# CM_CORE_AON__CKGEN register map
Vendor: Texas Instruments
Peripheral module from a debugger description file (folder DRA74xP_75xP_76xP_77xP).
Registers are 32-bit, access per field, reset values left out (the file's numbers can be read two ways) unless marked. A register's access mark holds for its fields unless they carry their own. Offsets are as the file gives them; lines under a group give offsets from that group; [hi:lo] are bit positions; {n}, {i} and the like mark numbered series; 'fields as' and 'values as' point back to an identical list; <NAME> marks a mode.

## CM_CORE_AON__CKGEN
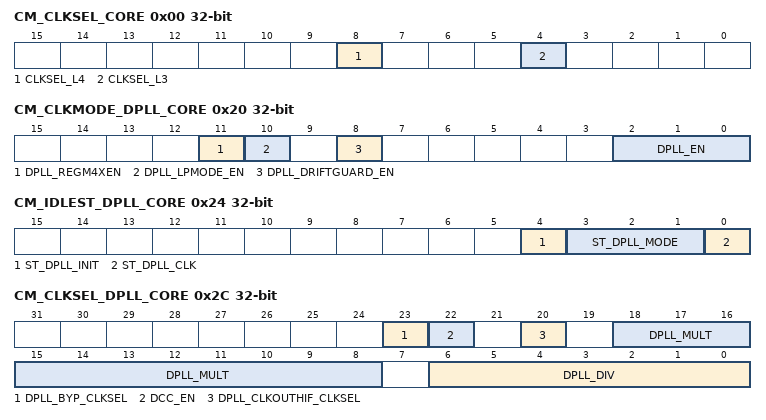
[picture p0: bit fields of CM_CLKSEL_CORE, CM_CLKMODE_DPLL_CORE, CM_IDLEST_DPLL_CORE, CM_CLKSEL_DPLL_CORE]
0x00 CM_CLKSEL_CORE — CORE module clock selection.
  [8] CLKSEL_L4 ro — Selects L4 interconnect clock (L4_clk)
    0=L3_CLK_DIV_1 (RESERVED); 1=L3_CLK_DIV_2 (L4_CLK is L3_CLK divided by 2)
  [4] CLKSEL_L3 rw — Selects L3 interconnect clock (L3_clk)
    0=CORE_CLK_DIV_1 (L3_CLK is CORE_CLK divided by 1); 1=CORE_CLK_DIV_2 (L3_CLK is CORE_CLK divided by 2)
0x08 CM_CLKSEL_ABE — ABE module clock selection.
  [1:0] CLKSEL_OPP rw — Selects the OPP divider ABE domain
    0=DIV_1 (ABE_CLK is divide by 1 of DPLL_ABE_X2_CLK); 1=DIV_2 (ABE_CLK is divide by 2 of DPLL_ABE_X2_CLK); 2=DIV_4 (ABE_CLK is divide by 4 of DPLL_ABE_X2_CLK)
0x10 CM_DLL_CTRL — Special register for DLL control
  [0] DLL_OVERRIDE rw — Control if DLL lock and code outputs are overriden or not
    0=NO_OVR; 1=OVR
0x20 CM_CLKMODE_DPLL_CORE — This register allows controlling the DPLL modes.
  [11] DPLL_REGM4XEN ro — Enable the REGM4XEN mode of the DPLL. Please check the DPLL documentation to check when this mode can be enabled.
    0=DISABLED (REGM4XEN mode of the DPLL is disabled)
  [10] DPLL_LPMODE_EN rw — Set the DPLL in Low Power mode. Check the DPLL documentation to see when this can be enabled.
    0=DISABLED (Low power mode of the DPLL is disabled); 1=ENABLED (Low power mode of the DPLL is enabled)
  [8] DPLL_DRIFTGUARD_EN rw — This bit allows to enable or disable the automatic recalibration feature of the DPLL. The DPLL will automatically start a recalibration process upon assertion of the DPLL's RECAL flag if this bit is set.
    0=DIASBLED (DRIFTGUARD feature is disabled); 1=ENABLED (DRIFTGUARD feature is enabled)
  [2:0] DPLL_EN rw — DPLL control.
    5=DPLL_LP_BYP_MODE (Put the DPLL in Idle Bypass Low Power mode.); 6=DPLL_FR_BYP_MODE (Put the DPLL in Idle Bypass Fast Relock mode.); 7=DPLL_LOCK_MODE (Enables the DPLL in Lock mode)
0x24 CM_IDLEST_DPLL_CORE ro — This register allows monitoring DPLL activity. This register is read only and automatically updated. [warm reset insensitive]
  [4] ST_DPLL_INIT — DPLL init status (for debug purpose).
    0=DPLL_NOTINIT; 1=DPLL_INIT
  [3:1] ST_DPLL_MODE — DPLL mode status (for debug purpose).
  [0] ST_DPLL_CLK — DPLL lock status
    0=DPLL_UNLOCKED; 1=DPLL_LOCKED
0x28 CM_AUTOIDLE_DPLL_CORE — This register provides automatic control over the DPLL activity.
  [2:0] AUTO_DPLL_MODE rw — DPLL automatic control.
    0=AUTO_CTL_DISABLE (DPLL auto control disabled); 1=AUTO_LP_STOP (The DPLL is automatically put in Low Power Stop mode when its DPLL generated clocks are not required anymore. It is also restarted automatically.); 2=AUTO_FR_STOP (The DPLL is automatically put in Fast Relock Stop mode when its DPLL generated clocks are not required anymore. It is also restarted automatically.); 5=AUTO_LP_BYP (The DPLL is automatically put in Idle Bypass Low Power mode when its DPLL generated clocks are not required anymore. It is also restarted automatically.); 6=AUTO_FR_BYP (The DPLL is automatically put in Idle Bypass Fast Relock mode when its DPLL generated clocks are not required anymore. It is also restarted automatically.)
0x2C CM_CLKSEL_DPLL_CORE — This register provides controls over the DPLL.
  [23] DPLL_BYP_CLKSEL rw — Allows control of the BYPASS clock of the PLL and the associated HSDIVIDER. Same as ULOWCLKEN on DPLL. In DPLL Locked mode, 0 - No impact 1 - No impact In DPLL Bypass mode, 0 - CLKINP is selected as the BYPASS clock for CLKOUT/CLKOUTX2 1 - CLKINPULOW is selected as the BYPASS clock for CLKOUT/CLKOUTX2
  [22] DCC_EN ro — Duty-cycle corrector for high frequency clock
    0=DISABLED (Duty-cycle corrector is disabled)
  [20] DPLL_CLKOUTHIF_CLKSEL rw — Selects the source of the DPLL CLKOUTHIF clock. Same as CLKINPHIFSEL pin on the DPLL
    0=SEL_DCO (CLKOUTHIF is generated from the DPLL oscillator (DCO)); 1=SEL_CLKINPHIF (CLKOUTHIF is generated from CLKINPHIF)
  [18:8] DPLL_MULT rw — DPLL multiplier factor (2 to 2047). (equal to input M of DPLL; M=2 to 2047 = DPLL multiplies by M). [warm reset insensitive]
  [6:0] DPLL_DIV rw — DPLL divider factor (0 to 127) (equal to input N of DPLL; actual division factor is N+1). [warm reset insensitive]
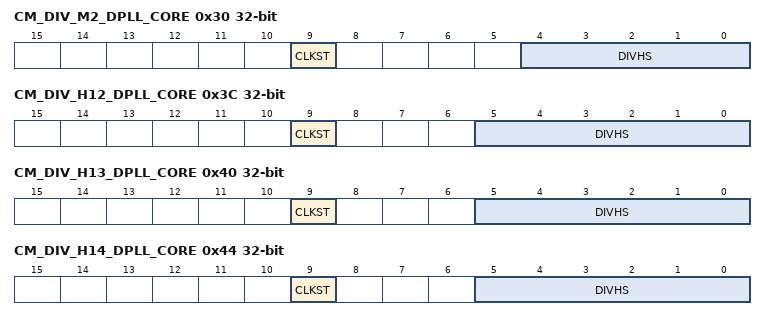
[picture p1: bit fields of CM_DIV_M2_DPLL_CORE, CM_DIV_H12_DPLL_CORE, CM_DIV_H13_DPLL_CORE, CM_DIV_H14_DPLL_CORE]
0x30 CM_DIV_M2_DPLL_CORE — This register provides controls over the M2 divider of the DPLL.
  [9] CLKST ro — DPLL CLKOUT status
    0=CLK_GATED (The clock output is gated); 1=CLK_ENABLED (The clock output is enabled)
  [4:0] DIVHS rw — This field programs the M2 post-divider factor (1 to 31) of DPLL_CORE.... .
    1=M2_=_/1; 2=M2_=_/2; 31=RESERVED (M2 = /31)
0x3C CM_DIV_H12_DPLL_CORE — This register provides controls over the CLKOUT2 o/p of the HSDIVIDER1.
  [9] CLKST ro — HSDIVIDER1 CLKOUT2 status
    values as CM_DIV_M2_DPLL_CORE.CLKST
  [5:0] DIVHS rw — This field programs the H12 post-divider factor (1 to 63) of DPLL_CORE.... .
    1=H12_=_/1; 2=H12_=_/2; 63=RESERVED (H12 = /63)
0x40 CM_DIV_H13_DPLL_CORE — This register provides controls over the CLKOUT3 o/p of the HSDIVIDER1.
  [9] CLKST ro — HSDIVIDER1 CLKOUT3 status
    values as CM_DIV_M2_DPLL_CORE.CLKST
  [5:0] DIVHS rw — This field programs the H13 post-divider factor (1 to 63) of DPLL_CORE.... .
    1=H13_=_/1; 2=H13_=_/2; 63=RESERVED (H13 = /63)
0x44 CM_DIV_H14_DPLL_CORE — This register provides controls over the CLKOUT4 o/p of the HSDIVIDER1.
  [9] CLKST ro — HSDIVIDER1 CLKOUT4 status
    values as CM_DIV_M2_DPLL_CORE.CLKST
  [5:0] DIVHS rw — This field programs the H14 post-divider factor (1 to 63) of DPLL_CORE. When a value of 63 is programmed in this register, HS divider will perform division by 2.5 that is divided by 2 at top level.... .
    1=H14_=_/1; 2=H14_=_/2; 63=RESERVED (H14 = /63)
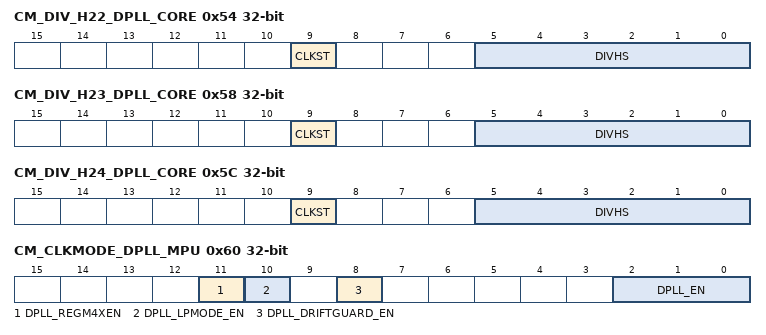
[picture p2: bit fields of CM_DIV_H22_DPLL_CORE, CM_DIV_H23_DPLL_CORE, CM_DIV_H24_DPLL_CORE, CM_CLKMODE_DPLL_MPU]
0x54 CM_DIV_H22_DPLL_CORE — This register provides controls over the CLKOUT2 o/p of the 2nd HSDIVIDER.
  [9] CLKST ro — HSDIVIDER2 CLKOUT2 status
    values as CM_DIV_M2_DPLL_CORE.CLKST
  [5:0] DIVHS rw — This field programs the H22 post-divider factor (1 to 63) of DPLL_CORE.... .
    1=H22_=_/1; 2=H22_=_/2; 63=RESERVED (H22 = /63)
0x58 CM_DIV_H23_DPLL_CORE — This register provides controls over the CLKOUT3 o/p of the 2nd HSDIVIDER.
  [9] CLKST ro — HSDIVIDER2 CLKOUT3 status
    values as CM_DIV_M2_DPLL_CORE.CLKST
  [5:0] DIVHS rw — This field programs the H23 post-divider factor (1 to 63) of DPLL_CORE.... .
    1=H23_=_/1; 2=H23_=_/2; 63=RESERVED (H23 = /63)
0x5C CM_DIV_H24_DPLL_CORE — This register provides controls over the CLKOUT4 o/p of the 2nd HSDIVIDER.
  [9] CLKST ro — HSDIVIDER2 CLKOUT4 status
    values as CM_DIV_M2_DPLL_CORE.CLKST
  [5:0] DIVHS rw — This field programs the H24 post-divider factor (1 to 63) of DPLL_CORE.... .
    1=H24_=_/1; 2=H24_=_/2; 63=RESERVED (H24 = /63)
0x60 CM_CLKMODE_DPLL_MPU — This register allows controlling the DPLL modes.
  fields as CM_CLKMODE_DPLL_CORE
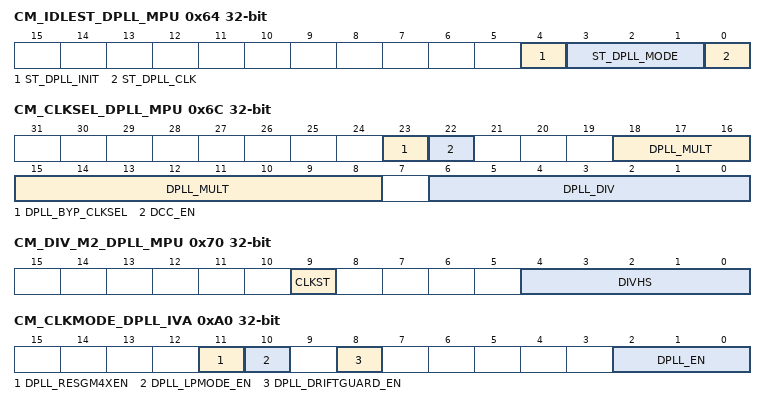
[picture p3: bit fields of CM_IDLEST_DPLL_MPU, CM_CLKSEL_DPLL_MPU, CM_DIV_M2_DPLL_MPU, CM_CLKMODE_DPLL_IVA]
0x64 CM_IDLEST_DPLL_MPU ro — This register allows monitoring DPLL activity. This register is read only and automatically updated. [warm reset insensitive]
  [4] ST_DPLL_INIT — DPLL init status (for debug purpose).
    0=DPLL_NOTINIT (DPLL is not init); 1=DPLL_INIT (DPLL has been init)
  [3:1] ST_DPLL_MODE — DPLL mode status (for debug purpose).
    0=TRANSIENT (Transient state. From reset to any LP idle state or from any power state to any power state (Power states are Low Power Stop mode, Fast Relock Stop mode, Idle Bypass Low Power mode and Idle Bypass Fast Relock mode).); 1=LP_STOP (The DPLL is in Low Power Stop mode.); 2=FR_STOP (The DPLL is in Fast Relock Stop mode.); 5=LP_BYP (The DPLL is in Idle Bypass Low Power mode.); 6=FR_BYP (The DPLL is in Idle Bypass Fast Relock mode.)
  [0] ST_DPLL_CLK — DPLL lock status
    0=DPLL_UNLOCKED (DPLL is either in bypass mode or in stop mode.); 1=DPLL_LOCKED (DPLL is LOCKED)
0x68 CM_AUTOIDLE_DPLL_MPU — This register provides automatic control over the DPLL activity.
  [2:0] AUTO_DPLL_MODE rw — DPLL automatic control;
    values as CM_AUTOIDLE_DPLL_CORE.AUTO_DPLL_MODE
0x6C CM_CLKSEL_DPLL_MPU — This register provides controls over the DPLL.
  [23] DPLL_BYP_CLKSEL ro — Only CLKINPULOW bypass clock supported for this PLL
  [22] DCC_EN rw — Duty-cycle corrector for high frequency clock
    0=DISABLED (Duty-cycle corrector is disabled); 1=ENABLED (Duty-cycle corrector is enabled)
  [18:8] DPLL_MULT rw — DPLL multiplier factor (2 to 2047). (equal to input M of DPLL; M=2 to 2047 = DPLL multiplies by M). [warm reset insensitive]
  [6:0] DPLL_DIV rw — DPLL divider factor (0 to 127) (equal to input N of DPLL; actual division factor is N+1). [warm reset insensitive]
0x70 CM_DIV_M2_DPLL_MPU — This register provides controls over the M2 divider of the DPLL.
  [9] CLKST ro — DPLL CLKOUT status
    values as CM_DIV_M2_DPLL_CORE.CLKST
  [4:0] DIVHS rw — This field programs the M2 post-divider factor (1 to 31) of DPLL_MPU.... .
    1=M2_=_/1; 2=M2_=_/2; 31=RESERVED (M2 = /31)
0x9C CM_BYPCLK_DPLL_MPU — Control MPU PLL BYPASS clock. [warm reset insensitive]
  [1:0] CLKSEL rw — Select the DPLL MPU bypass clock
0xA0 CM_CLKMODE_DPLL_IVA — This register allows controlling the DPLL modes.
  [11] DPLL_RESGM4XEN ro — Enable the REGM4XEN mode of the DPLL. Please check the DPLL documentation to check when this mode can be enabled.
    0=DISABLED (REGM4XEN mode of the DPLL is disabled)
  [10] DPLL_LPMODE_EN rw — Set the DPLL in Low Power mode. Check the DPLL documentation to see when this can be enabled.
    values as CM_CLKMODE_DPLL_CORE.DPLL_LPMODE_EN
  [8] DPLL_DRIFTGUARD_EN rw — This bit allows to enable or disable the automatic recalibration feature of the DPLL. The DPLL will automatically start a recalibration process upon assertion of the DPLL's RECAL flag if this bit is set.
    values as CM_CLKMODE_DPLL_CORE.DPLL_DRIFTGUARD_EN
  [2:0] DPLL_EN rw — DPLL control.
    values as CM_CLKMODE_DPLL_CORE.DPLL_EN
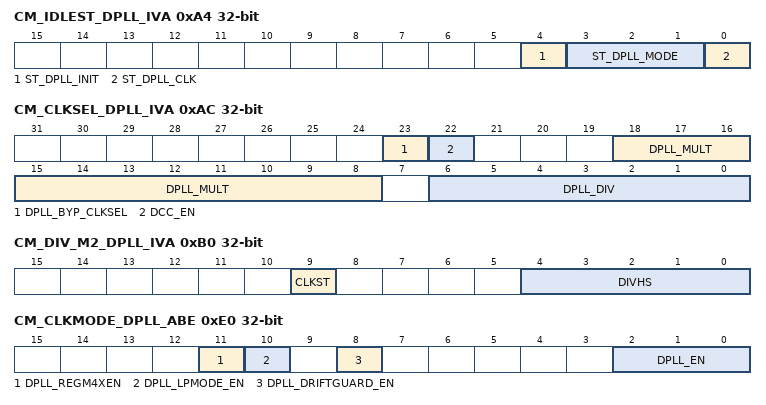
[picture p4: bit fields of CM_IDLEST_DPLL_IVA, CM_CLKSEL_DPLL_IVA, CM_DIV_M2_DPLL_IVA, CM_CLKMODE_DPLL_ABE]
0xA4 CM_IDLEST_DPLL_IVA ro — This register allows monitoring DPLL activity. This register is read only and automatically updated. [warm reset insensitive]
  [4] ST_DPLL_INIT — DPLL init status (for debug purpose)
    values as CM_IDLEST_DPLL_MPU.ST_DPLL_INIT
  [3:1] ST_DPLL_MODE — DPLL mode status (for debug purpose).
    values as CM_IDLEST_DPLL_MPU.ST_DPLL_MODE
  [0] ST_DPLL_CLK — DPLL lock status
    values as CM_IDLEST_DPLL_MPU.ST_DPLL_CLK
0xA8 CM_AUTOIDLE_DPLL_IVA — This register provides automatic control over the DPLL activity.
  fields as CM_AUTOIDLE_DPLL_MPU
0xAC CM_CLKSEL_DPLL_IVA — This register provides controls over the DPLL.
  [23] DPLL_BYP_CLKSEL rw — Allows control of the BYPASS clock of the PLL and the associated HSDIVIDER. Same as ULOWCLKEN on DPLL. In DPLL Locked mode, 0 - No impact 1 - No impact In DPLL Bypass mode, 0 - CLKINP is selected as the BYPASS clock for CLKOUT/CLKOUTX2 1 - CLKINPULOW is selected as the BYPASS clock for CLKOUT/CLKOUTX2
  [22] DCC_EN ro — Duty-cycle corrector for high frequency clock
    0=DISABLED (Duty-cycle corrector is disabled)
  [18:8] DPLL_MULT rw — DPLL multiplier factor (2 to 2047). (equal to input M of DPLL; M=2 to 2047 = DPLL multiplies by M). [warm reset insensitive]
  [6:0] DPLL_DIV rw — DPLL divider factor (0 to 127) (equal to input N of DPLL; actual division factor is N+1). [warm reset insensitive]
0xB0 CM_DIV_M2_DPLL_IVA — This register provides controls over the M2 divider of the DPLL.
  [9] CLKST ro — DPLL CLKOUT status
    values as CM_DIV_M2_DPLL_CORE.CLKST
  [4:0] DIVHS rw — This field programs the M2 post-divider factor (1 to 31) of DPLL_IVA.... .
    1=M2_=_/1; 2=M2_=_/2; 31=RESERVED (M2 = /31)
0xDC CM_BYPCLK_DPLL_IVA — Control IVA PLL BYPASS clock. [warm reset insensitive]
  [1:0] CLKSEL rw — Select the DPLL IVA bypass clock
    0=CORE_X2_CLK_DIV_1 (DPLL_IVA bypass clock is CORE_X2_CLK divided by 1); 1=CORE_X2_CLK_DIV_2 (DPLL_IVA bypass clock is CORE_X2_CLK divided by 2); 2=CORE_X2_CLK_DIV_4 (DPLL_IVA bypass clock is CORE_X2_CLK divided by 4); 3=CORE_X2_CLK_DIV_8 (DPLL_IVA bypass clock is CORE_X2_CLK divided by 8)
0xE0 CM_CLKMODE_DPLL_ABE — This register allows controlling the DPLL modes.
  [11] DPLL_REGM4XEN rw — Enable the REGM4XEN mode of the DPLL. Please check the DPLL documentation to check when this mode can be enabled.
    0=DISABLED (REGM4XEN mode of the DPLL is disabled); 1=ENABLE (REGM4XEN mode of the DPLL is enabled)
  [10] DPLL_LPMODE_EN rw — Set the DPLL in Low Power mode. Check the DPLL documentation to see when this can be enabled.
    values as CM_CLKMODE_DPLL_CORE.DPLL_LPMODE_EN
  [8] DPLL_DRIFTGUARD_EN rw — This bit allows to enable or disable the automatic recalibration feature of the DPLL. The DPLL will automatically start a recalibration process upon assertion of the DPLL's RECAL flag if this bit is set.
    values as CM_CLKMODE_DPLL_CORE.DPLL_DRIFTGUARD_EN
  [2:0] DPLL_EN rw — DPLL control.
    values as CM_CLKMODE_DPLL_CORE.DPLL_EN
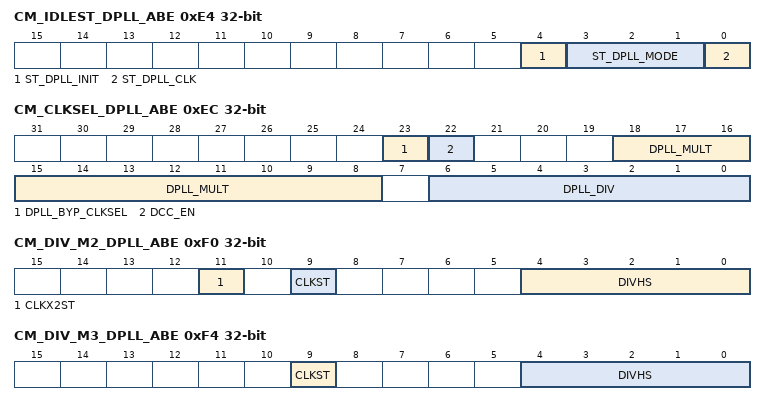
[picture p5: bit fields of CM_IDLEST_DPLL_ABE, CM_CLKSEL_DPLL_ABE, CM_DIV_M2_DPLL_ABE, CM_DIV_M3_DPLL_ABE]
0xE4 CM_IDLEST_DPLL_ABE ro — This register allows monitoring DPLL activity. This register is read only and automatically updated. [warm reset insensitive]
  fields as CM_IDLEST_DPLL_MPU
0xE8 CM_AUTOIDLE_DPLL_ABE — This register provides automatic control over the DPLL activity.
  [2:0] AUTO_DPLL_MODE rw — DPLL automatic control;
0xEC CM_CLKSEL_DPLL_ABE — This register provides controls over the DPLL.
  [23] DPLL_BYP_CLKSEL ro — Only CLKINPULOW bypass clock supported for this PLL
  [22] DCC_EN ro — Duty-cycle corrector for high frequency clock
    0=DISABLED (Duty-cycle corrector is disabled)
  [18:8] DPLL_MULT rw — DPLL multiplier factor (2 to 2047). (equal to input M of DPLL; M=2 to 2047 = DPLL multiplies by M). [warm reset insensitive]
  [6:0] DPLL_DIV rw — DPLL divider factor (0 to 127) (equal to input N of DPLL; actual division factor is N+1). [warm reset insensitive]
0xF0 CM_DIV_M2_DPLL_ABE — This register provides controls over the M2 divider of the DPLL.
  [11] CLKX2ST ro — DPLL CLKOUTX2 status
    0=CLK_GATED; 1=CLK_ENABLED
  [9] CLKST ro — DPLL CLKOUT status
    0=CLK_GATED; 1=CLK_ENABLED
  [4:0] DIVHS rw — This field programs the M2 post-divider factor (1 to 31) of DPLL_ABE.... .
    1=M2_=_/1; 2=M2_=_/2; 31=RESERVED (M2 = /31)
0xF4 CM_DIV_M3_DPLL_ABE — This register provides controls over the M3 divider of the DPLL.
  [9] CLKST ro — DPLL CLKOUTHIF status
    values as CM_DIV_M2_DPLL_CORE.CLKST
  [4:0] DIVHS rw — This field programs the M3 post-divider factor (1 to 31) of DPLL_ABE.... .
    1=M3_=_/1; 2=M3_=_/2; 31=RESERVED (M3 = /31)
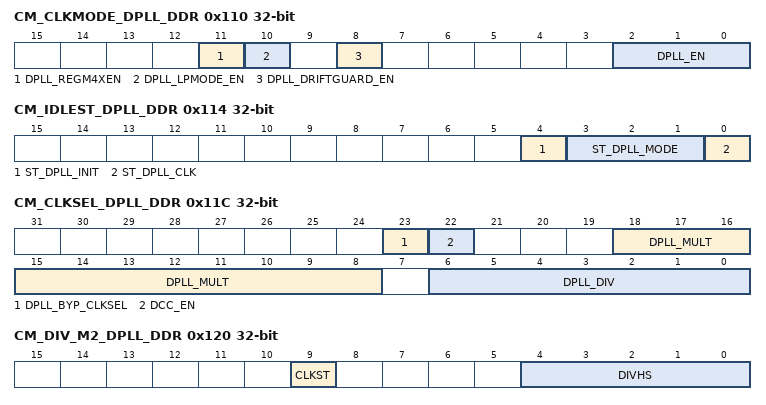
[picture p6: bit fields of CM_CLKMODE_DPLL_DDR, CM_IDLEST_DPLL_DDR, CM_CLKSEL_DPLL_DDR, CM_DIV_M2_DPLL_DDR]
0x110 CM_CLKMODE_DPLL_DDR — This register allows controlling the DPLL modes.
  fields as CM_CLKMODE_DPLL_CORE
0x114 CM_IDLEST_DPLL_DDR ro — This register allows monitoring DPLL activity. This register is read only and automatically updated. [warm reset insensitive]
  fields as CM_IDLEST_DPLL_MPU
0x118 CM_AUTOIDLE_DPLL_DDR — This register provides automatic control over the DPLL activity.
  fields as CM_AUTOIDLE_DPLL_MPU
0x11C CM_CLKSEL_DPLL_DDR — This register provides controls over the DPLL.
  [23] DPLL_BYP_CLKSEL rw — Allows control of the BYPASS clock of the PLL and the associated HSDIVIDER. Same as ULOWCLKEN on DPLL. In DPLL Locked mode, 0 - No impact 1 - No impact In DPLL Bypass mode, 0 - CLKINP is selected as the BYPASS clock for CLKOUT/CLKOUTX2 1 - CLKINPULOW is selected as the BYPASS clock for CLKOUT/CLKOUTX2
  [22] DCC_EN rw — Duty-cycle corrector for high frequency clock
    values as CM_CLKSEL_DPLL_MPU.DCC_EN
  [18:8] DPLL_MULT rw — DPLL multiplier factor (2 to 2047). (equal to input M of DPLL; M=2 to 2047 = DPLL multiplies by M). [warm reset insensitive]
  [6:0] DPLL_DIV rw — DPLL divider factor (0 to 127) (equal to input N of DPLL; actual division factor is N+1). [warm reset insensitive]
0x120 CM_DIV_M2_DPLL_DDR — This register provides controls over the M2 divider of the DPLL.
  [9] CLKST ro — DPLL CLKOUT status
    values as CM_DIV_M2_DPLL_CORE.CLKST
  [4:0] DIVHS rw — This field programs the M2 post-divider factor (1 to 31) of DPLL_DDR.... .
    1=M2_=_/1; 2=M2_=_/2; 31=RESERVED (M2 = /31)
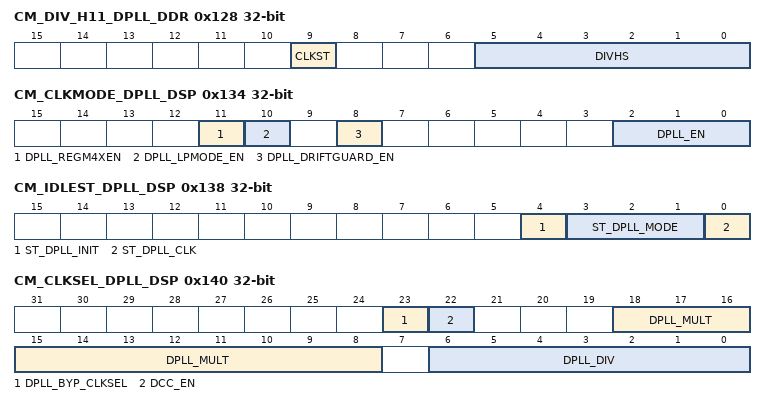
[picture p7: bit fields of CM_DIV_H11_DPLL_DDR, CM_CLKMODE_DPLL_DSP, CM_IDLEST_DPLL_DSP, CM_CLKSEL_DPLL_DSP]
0x128 CM_DIV_H11_DPLL_DDR — This register provides controls over the CLKOUT1 o/p of the HSDIVIDER1.
  [9] CLKST ro — HSDIVIDER1 CLKOUT1 status
    values as CM_DIV_M2_DPLL_CORE.CLKST
  [5:0] DIVHS rw — This field programs the H11 post-divider factor (1 to 63) of DPLL_DDR.... .
    1=H11_=_/1; 2=H11_=_/2; 63=RESERVED (H11 = /63)
0x134 CM_CLKMODE_DPLL_DSP — This register allows controlling the DPLL modes.
  fields as CM_CLKMODE_DPLL_CORE
0x138 CM_IDLEST_DPLL_DSP ro — This register allows monitoring DPLL activity. This register is read only and automatically updated. [warm reset insensitive]
  fields as CM_IDLEST_DPLL_IVA
0x13C CM_AUTOIDLE_DPLL_DSP — This register provides automatic control over the DPLL activity.
  fields as CM_AUTOIDLE_DPLL_MPU
0x140 CM_CLKSEL_DPLL_DSP — This register provides controls over the DPLL.
  fields as CM_CLKSEL_DPLL_IVA
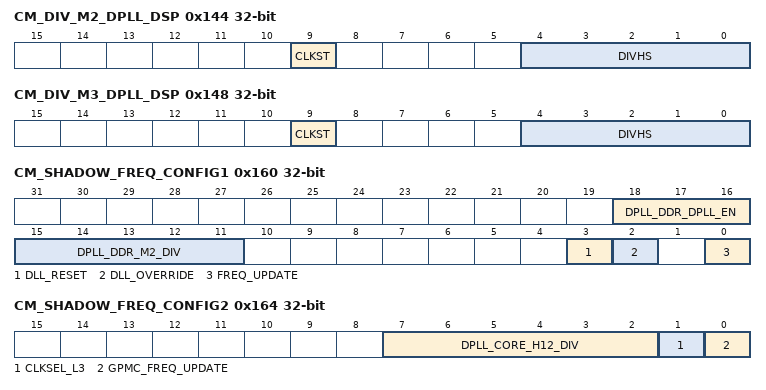
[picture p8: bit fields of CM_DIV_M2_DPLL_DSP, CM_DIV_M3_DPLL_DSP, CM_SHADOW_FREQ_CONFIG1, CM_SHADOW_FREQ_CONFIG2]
0x144 CM_DIV_M2_DPLL_DSP — This register provides controls over the M2 divider of the DPLL.
  [9] CLKST ro — DPLL CLKOUT status
    0=CLK_GATED; 1=CLK_ENABLED
  [4:0] DIVHS rw — This field programs the M2 post-divider factor (1 to 31) of DPLL_DSP.... .
    1=M2_=_/1; 2=M2_=_/2; 31=RESERVED (M2 = /31)
0x148 CM_DIV_M3_DPLL_DSP — This register provides controls over the M3 divider of the DPLL.
  [9] CLKST ro — DPLL CLKOUTHIF status
    values as CM_DIV_M2_DPLL_CORE.CLKST
  [4:0] DIVHS rw — This field programs the M3 post-divider factor (1 to 31) of DPLL_DSP.... .
    1=M3_=_/1; 2=M3_=_/2; 31=RESERVED (M3 = /31)
0x154 CM_BYPCLK_DPLL_DSP — Control IVA PLL BYPASS clock. [warm reset insensitive]
  fields as CM_BYPCLK_DPLL_IVA
0x160 CM_SHADOW_FREQ_CONFIG1 — Shadow register to program new DPLL configuration affecting EMIF and GPMC (L3 clock) functional frequency during DVFS. The PRCM h/w automatically applies the new configuration after EMIF/GPMC have been put in idle state.
  [18:16] DPLL_DDR_DPLL_EN rw — Shadow register forCM_CLKMODE_DPLL_DDR.DPLL_EN. The main register is automatically loaded with the shadow register value after EMIF IDLE if the FREQ_UPDATE field is set to '1'.
    values as CM_CLKMODE_DPLL_CORE.DPLL_EN
  [15:11] DPLL_DDR_M2_DIV rw — Shadow register forCM_DIV_M2_DPLL_DDR.DIVHS. The main register is automatically loaded with the shadow register value after EMIF IDLE if the FREQ_UPDATE field is set to '1'. Divide value from 1 to 31.
  [3] DLL_RESET rw — Specify if DLL should be reset or not during the frequency change hardware sequence.
    0=NO_RESET (DLL is not reset during the frequency change hardware sequence); 1=RESET (DLL is reset automatically during the frequency change hardware sequence)
  [2] DLL_OVERRIDE rw — Shadow register forCM_DLL_CTRL.DLL_OVERRIDE.The main register is automatically loaded with the shadow register value after EMIF IDLE if the FREQ_UPDATE field is set to '1'.
    0=NO_OVR (Lock and code outputs are not overriden); 1=OVR (Lock output is overriden to '1' and code output is overriden with a value coming from control module.)
  [0] FREQ_UPDATE rw — Writing '1' indicates that a new configuration is available. It is automatically cleared by h/w after the configuration has been applied.
0x164 CM_SHADOW_FREQ_CONFIG2 — Shadow register to program new DPLL configuration affecting GPMC (L3 clock) functional frequency during DVFS. The PRCM h/w automatically applies the new configuration after EMIF/GPMC have been put in idle state.
  [7:2] DPLL_CORE_H12_DIV rw — Shadow register forCM_DIV_H12_DPLL_CORE.DIVHS. The main register is automatically loaded with the shadow register value after GPMC IDLE if the CM_SHADOW_FREQ_CONFIG1.FREQ_UPDATE field is set to '1' and GPMC_FREQ_UPDATE is set to '1'. Divide value from 1 to 31.
  [1] CLKSEL_L3 rw — Shadow register forCM_CLKSEL_CORE.CLKSEL_L3. The main register is automatically loaded with the shadow register value after GPMC IDLE if the CM_SHADOW_FREQ_CONFIG1.FREQ_UPDATE field is set to '1' and GPMC_FREQ_UPDATE is set to '1'.
    values as CM_CLKSEL_CORE.CLKSEL_L3
  [0] GPMC_FREQ_UPDATE rw — Controls whether or not GPMC has to be put automatically into idle during the frequency change operation.
    0=DISABLED (GPMC is not put automatically into idle during frequency change operation.); 1=ENABLED (GPMC is put automatically into idle during frequency change operation.)
0x170 CM_DYN_DEP_PRESCAL — Control the time unit of the sliding window for dynamic dependencies (auto-sleep feature).
  [5:0] PRESCAL rw — Time unit is equal to (PRESCAL + 1) L4 clock cycles.
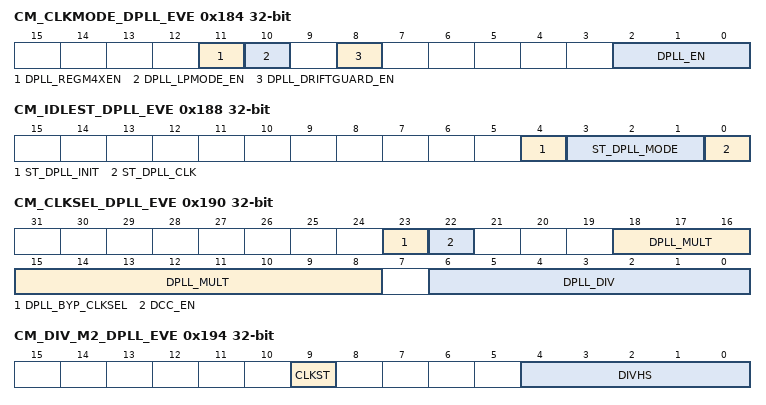
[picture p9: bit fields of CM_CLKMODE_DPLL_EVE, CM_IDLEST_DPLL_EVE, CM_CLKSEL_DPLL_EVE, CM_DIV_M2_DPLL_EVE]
0x184 CM_CLKMODE_DPLL_EVE — This register allows controlling the DPLL modes.
  fields as CM_CLKMODE_DPLL_CORE
0x188 CM_IDLEST_DPLL_EVE ro — This register allows monitoring DPLL activity. This register is read only and automatically updated. [warm reset insensitive]
  fields as CM_IDLEST_DPLL_IVA
0x18C CM_AUTOIDLE_DPLL_EVE — This register provides automatic control over the DPLL activity.
  fields as CM_AUTOIDLE_DPLL_MPU
0x190 CM_CLKSEL_DPLL_EVE — This register provides controls over the DPLL.
  fields as CM_CLKSEL_DPLL_IVA
0x194 CM_DIV_M2_DPLL_EVE — This register provides controls over the M2 divider of the DPLL.
  [9] CLKST ro — DPLL CLKOUT status
    values as CM_DIV_M2_DPLL_CORE.CLKST
  [4:0] DIVHS rw — This field programs the M2 post-divider factor (1 to 31) of DPLL_EVE.... .
    1=M2_=_/1; 2=M2_=_/2; 31=RESERVED (M2 = /31)
0x1A4 CM_BYPCLK_DPLL_EVE — Control IVA PLL BYPASS clock. [warm reset insensitive]
  [1:0] CLKSEL rw — Select the DPLL IVA bypass clock
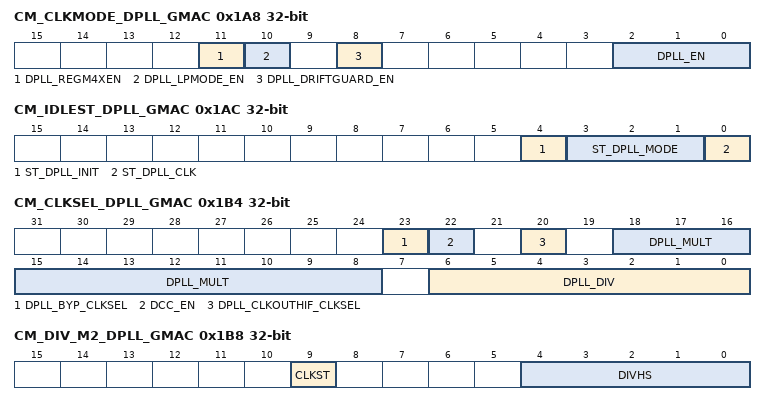
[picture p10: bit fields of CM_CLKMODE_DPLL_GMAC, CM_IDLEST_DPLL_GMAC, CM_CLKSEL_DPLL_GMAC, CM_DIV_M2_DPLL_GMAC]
0x1A8 CM_CLKMODE_DPLL_GMAC — This register allows controlling the DPLL modes.
  fields as CM_CLKMODE_DPLL_CORE
0x1AC CM_IDLEST_DPLL_GMAC ro — This register allows monitoring DPLL activity. This register is read only and automatically updated. [warm reset insensitive]
  fields as CM_IDLEST_DPLL_MPU
0x1B0 CM_AUTOIDLE_DPLL_GMAC — This register provides automatic control over the DPLL activity.
  fields as CM_AUTOIDLE_DPLL_MPU
0x1B4 CM_CLKSEL_DPLL_GMAC — This register provides controls over the DPLL.
  [23] DPLL_BYP_CLKSEL rw — Allows control of the BYPASS clock of the PLL and the associated HSDIVIDER. Same as ULOWCLKEN on DPLL. In DPLL Locked mode, 0 - No impact 1 - No impact In DPLL Bypass mode, 0 - CLKINP is selected as the BYPASS clock for CLKOUT/CLKOUTX2 1 - CLKINPULOW is selected as the BYPASS clock for CLKOUT/CLKOUTX2
  [22] DCC_EN rw — Duty-cycle corrector for high frequency clock
    values as CM_CLKSEL_DPLL_MPU.DCC_EN
  [20] DPLL_CLKOUTHIF_CLKSEL rw — Selects the source of the DPLL CLKOUTHIF clock. Same as CLKINPHIFSEL pin on the DPLL
    values as CM_CLKSEL_DPLL_CORE.DPLL_CLKOUTHIF_CLKSEL
  [18:8] DPLL_MULT rw — DPLL multiplier factor (2 to 2047). (equal to input M of DPLL; M=2 to 2047 = DPLL multiplies by M). [warm reset insensitive]
  [6:0] DPLL_DIV rw — DPLL divider factor (0 to 127) (equal to input N of DPLL; actual division factor is N+1). [warm reset insensitive]
0x1B8 CM_DIV_M2_DPLL_GMAC — This register provides controls over the M2 divider of the DPLL.
  [9] CLKST ro — DPLL CLKOUT status
    values as CM_DIV_M2_DPLL_CORE.CLKST
  [4:0] DIVHS rw — This field programs the M2 post-divider factor (1 to 31) of DPLL_GMAC.... .
    1=M2_=_/1; 2=M2_=_/2; 31=RESERVED (M2 = /31)
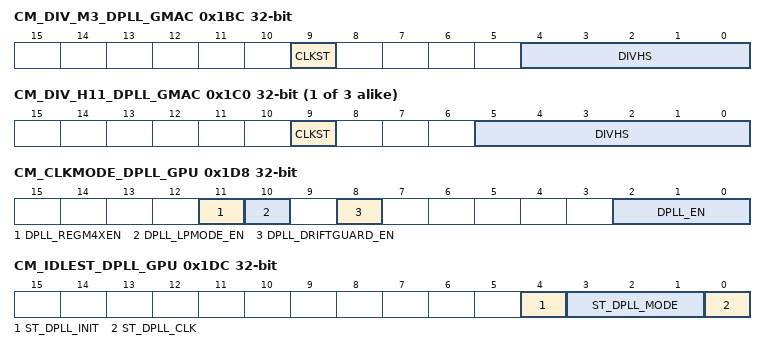
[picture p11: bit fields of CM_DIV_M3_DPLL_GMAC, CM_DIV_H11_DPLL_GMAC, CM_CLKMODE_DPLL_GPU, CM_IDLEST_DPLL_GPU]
0x1BC CM_DIV_M3_DPLL_GMAC — This register provides controls over the M3 divider of the DPLL.
  [9] CLKST ro — DPLL CLKOUTHIF status
    values as CM_DIV_M2_DPLL_CORE.CLKST
  [4:0] DIVHS rw — This field programs the M3 post-divider factor (1 to 31) of DPLL_GMAC.... .
    1=M3_=_/1; 2=M3_=_/2; 31=RESERVED (M3 = /31)
{0x194+4i} CM_DIV_H{i}_DPLL_GMAC (i=11..13) — This register provides controls over the CLKOUT{i-10} o/p of the HSDIVIDER1.
  [9] CLKST ro — HSDIVIDER1 CLKOUT{i-10} status
    values as CM_DIV_M2_DPLL_CORE.CLKST
  [5:0] DIVHS rw — This field programs the H{i} post-divider factor (1 to 63) of DPLL_GMAC.... .
    1=H{i}_=_/1; 2=H{i}_=_/2; 63=RESERVED (H{i} = /63)
0x1D8 CM_CLKMODE_DPLL_GPU — This register allows controlling the DPLL modes.
  fields as CM_CLKMODE_DPLL_CORE
0x1DC CM_IDLEST_DPLL_GPU ro — This register allows monitoring DPLL activity. This register is read only and automatically updated. [warm reset insensitive]
  fields as CM_IDLEST_DPLL_CORE
0x1E0 CM_AUTOIDLE_DPLL_GPU — This register provides automatic control over the DPLL activity.
  fields as CM_AUTOIDLE_DPLL_CORE
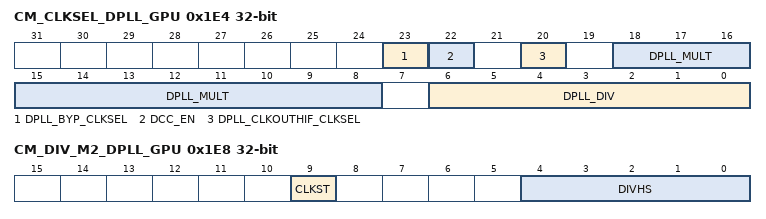
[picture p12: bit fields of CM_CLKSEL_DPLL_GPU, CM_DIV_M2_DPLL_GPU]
0x1E4 CM_CLKSEL_DPLL_GPU — This register provides controls over the DPLL.
  [23] DPLL_BYP_CLKSEL rw — Allows control of the BYPASS clock of the PLL and the associated HSDIVIDER. Same as ULOWCLKEN on DPLL. In DPLL Locked mode, 0 - No impact 1 - No impact In DPLL Bypass mode, 0 - CLKINP is selected as the BYPASS clock for CLKOUT/CLKOUTX2 1 - CLKINPULOW is selected as the BYPASS clock for CLKOUT/CLKOUTX2
  [22] DCC_EN ro — Duty-cycle corrector for high frequency clock
    0=DISABLED
  [20] DPLL_CLKOUTHIF_CLKSEL rw — Selects the source of the DPLL CLKOUTHIF clock. Same as CLKINPHIFSEL pin on the DPLL
    0=SEL_DCO; 1=SEL_CLKINPHIF
  [18:8] DPLL_MULT rw — DPLL multiplier factor (2 to 2047). (equal to input M of DPLL; M=2 to 2047 = DPLL multiplies by M). [warm reset insensitive]
  [6:0] DPLL_DIV rw — DPLL divider factor (0 to 127) (equal to input N of DPLL; actual division factor is N+1). [warm reset insensitive]
0x1E8 CM_DIV_M2_DPLL_GPU — This register provides controls over the M2 divider of the DPLL.
  [9] CLKST ro — DPLL CLKOUT status
    values as CM_DIV_M2_DPLL_CORE.CLKST
  [4:0] DIVHS rw — This field programs the M2 post-divider factor (1 to 31) of DPLL_GPU.... .
    1=M2_=_/1; 2=M2_=_/2; 31=RESERVED (M2 = /31)
